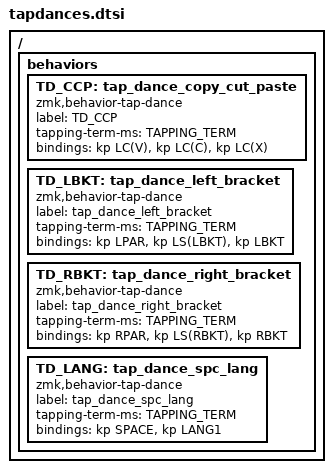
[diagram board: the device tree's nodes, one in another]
/{
  behaviors {
    TD_CCP: tap_dance_copy_cut_paste {
      compatible = "zmk,behavior-tap-dance";
      label = "TD_CCP";
      #binding-cells = <0>;
      tapping-term-ms = <TAPPING_TERM>;
      bindings = <&kp LC(V)>, <&kp LC(C)>, <&kp LC(X)>;
    };
    TD_LBKT: tap_dance_left_bracket {
      compatible = "zmk,behavior-tap-dance";
      label = "tap_dance_left_bracket";
      #binding-cells = <0>;
      tapping-term-ms = <TAPPING_TERM>;
      bindings = <&kp LPAR>, <&kp LS(LBKT)>, <&kp LBKT>;
    };
    TD_RBKT: tap_dance_right_bracket {
      compatible = "zmk,behavior-tap-dance";
      label = "tap_dance_right_bracket";
      #binding-cells = <0>;
      tapping-term-ms = <TAPPING_TERM>;
      bindings = <&kp RPAR>, <&kp LS(RBKT)>, <&kp RBKT>;
    };
    TD_LANG: tap_dance_spc_lang {
      compatible = "zmk,behavior-tap-dance";
      label = "tap_dance_spc_lang";
      #binding-cells = <0>;
      tapping-term-ms = <TAPPING_TERM>;
      bindings = <&kp SPACE>, <&kp LANG1>;
    };
  };
};
